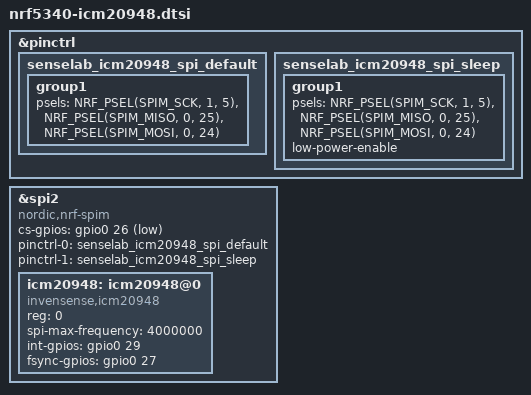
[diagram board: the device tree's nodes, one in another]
#include <zephyr/dt-bindings/gpio/gpio.h>
#include <zephyr/dt-bindings/pinctrl/nrf-pinctrl.h>

/* Both Phase 1 boards use this same populated ICM-20948 connection. */
&pinctrl {
	senselab_icm20948_spi_default: senselab_icm20948_spi_default {
		group1 {
			psels = <NRF_PSEL(SPIM_SCK, 1, 5)>,
				<NRF_PSEL(SPIM_MISO, 0, 25)>,
				<NRF_PSEL(SPIM_MOSI, 0, 24)>;
		};
	};

	senselab_icm20948_spi_sleep: senselab_icm20948_spi_sleep {
		group1 {
			psels = <NRF_PSEL(SPIM_SCK, 1, 5)>,
				<NRF_PSEL(SPIM_MISO, 0, 25)>,
				<NRF_PSEL(SPIM_MOSI, 0, 24)>;
			low-power-enable;
		};
	};
};

&spi2 {
	compatible = "nordic,nrf-spim";
	status = "okay";
	cs-gpios = <&gpio0 26 GPIO_ACTIVE_LOW>;
	pinctrl-0 = <&senselab_icm20948_spi_default>;
	pinctrl-1 = <&senselab_icm20948_spi_sleep>;
	pinctrl-names = "default", "sleep";

	icm20948: icm20948@0 {
		compatible = "invensense,icm20948";
		reg = <0>;
		spi-max-frequency = <4000000>;
		int-gpios = <&gpio0 29 GPIO_ACTIVE_HIGH>;
		fsync-gpios = <&gpio0 27 GPIO_ACTIVE_HIGH>;
		status = "okay";
	};
};
